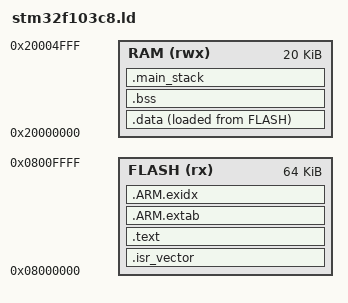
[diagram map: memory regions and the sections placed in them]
ENTRY(Reset_Handler)
MEMORY {
 FLASH (rx) : ORIGIN = 0x08000000, LENGTH = 64K
 RAM (rwx) : ORIGIN = 0x20000000, LENGTH = 20K
}
_estack = ORIGIN(RAM) + LENGTH(RAM);
_stack_reserve = 1024;
SECTIONS {
 .isr_vector : { KEEP(*(.isr_vector)) } > FLASH
 .text : { *(.text*) *(.rodata*) KEEP(*(.init)) KEEP(*(.fini)) . = ALIGN(4); } > FLASH
 .ARM.extab : { *(.ARM.extab*) } > FLASH
 .ARM.exidx : { *(.ARM.exidx*) } > FLASH
 _sidata = LOADADDR(.data);
 .data : { . = ALIGN(4); _sdata = .; *(.data*) . = ALIGN(4); _edata = .; } > RAM AT > FLASH
 .bss (NOLOAD) : { . = ALIGN(8); _sbss = .; *(.bss*) *(COMMON) . = ALIGN(8); _ebss = .; } > RAM
 _end = .;
 .main_stack _estack - _stack_reserve (NOLOAD) : { . = . + _stack_reserve; } > RAM
 ASSERT(_ebss <= _estack - _stack_reserve, "SRAM overflow: leave 1 KiB for MSP/ISR stack")
}
